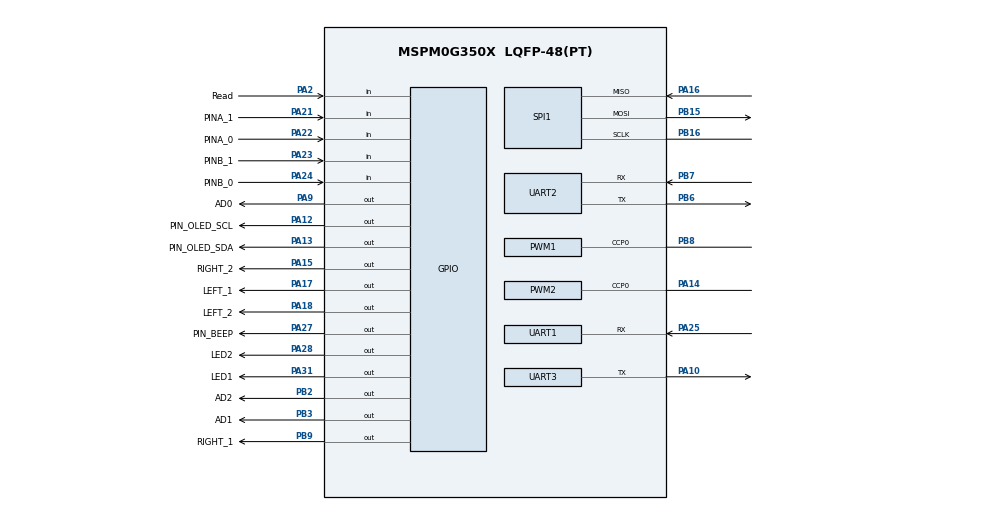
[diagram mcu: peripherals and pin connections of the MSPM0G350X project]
/**
 * @cliArgs --device "MSPM0G350X" --part "Default" --package "LQFP-48(PT)" --product "mspm0_sdk@2.10.00.04"
 * @versions {"tool":"1.26.2+4477"}
 */

/**
 * Import the modules used in this configuration.
 */
const GPIO   = scripting.addModule("/ti/driverlib/GPIO", {}, false);
const GPIO1  = GPIO.addInstance();
const GPIO2  = GPIO.addInstance();
const GPIO3  = GPIO.addInstance();
const GPIO4  = GPIO.addInstance();
const GPIO5  = GPIO.addInstance();
const GPIO6  = GPIO.addInstance();
const GPIO7  = GPIO.addInstance();
const PWM    = scripting.addModule("/ti/driverlib/PWM", {}, false);
const PWM1   = PWM.addInstance();
const PWM2   = PWM.addInstance();
const SPI    = scripting.addModule("/ti/driverlib/SPI", {}, false);
const SPI1   = SPI.addInstance();
const SYSCTL = scripting.addModule("/ti/driverlib/SYSCTL");
const TIMER  = scripting.addModule("/ti/driverlib/TIMER", {}, false);
const TIMER1 = TIMER.addInstance();
const UART   = scripting.addModule("/ti/driverlib/UART", {}, false);
const UART1  = UART.addInstance();
const UART2  = UART.addInstance();
const UART3  = UART.addInstance();

/**
 * Write custom configuration values to the imported modules.
 */
const divider7       = system.clockTree["PLL_PDIV"];
divider7.divideValue = 2;

const divider9       = system.clockTree["UDIV"];
divider9.divideValue = 2;

const multiplier2         = system.clockTree["PLL_QDIV"];
multiplier2.multiplyValue = 5;

const mux8       = system.clockTree["HSCLKMUX"];
mux8.inputSelect = "HSCLKMUX_SYSPLL2X";

GPIO1.$name                         = "GPIO_OLED";
GPIO1.associatedPins.create(2);
GPIO1.associatedPins[0].$name       = "PIN_OLED_SDA";
GPIO1.associatedPins[0].pin.$assign = "PA13";
GPIO1.associatedPins[1].$name       = "PIN_OLED_SCL";
GPIO1.associatedPins[1].pin.$assign = "PA12";

const Board = scripting.addModule("/ti/driverlib/Board", {}, false);

GPIO2.$name                         = "GPIO_MOTOR";
GPIO2.associatedPins.create(4);
GPIO2.associatedPins[0].$name       = "LEFT_1";
GPIO2.associatedPins[0].pin.$assign = "PA17";
GPIO2.associatedPins[1].$name       = "LEFT_2";
GPIO2.associatedPins[1].pin.$assign = "PA18";
GPIO2.associatedPins[2].$name       = "RIGHT_1";
GPIO2.associatedPins[2].pin.$assign = "PB9";
GPIO2.associatedPins[3].$name       = "RIGHT_2";
GPIO2.associatedPins[3].pin.$assign = "PA15";

GPIO3.$name                              = "GPIO_Grayscale";
GPIO3.associatedPins.create(4);
GPIO3.associatedPins[0].direction        = "INPUT";
GPIO3.associatedPins[0].ioStructure      = "SD";
GPIO3.associatedPins[0].$name            = "Read";
GPIO3.associatedPins[0].internalResistor = "PULL_DOWN";
GPIO3.associatedPins[0].pin.$assign      = "PA2";
GPIO3.associatedPins[1].$name            = "AD0";
GPIO3.associatedPins[1].pin.$assign      = "PA9";
GPIO3.associatedPins[2].$name            = "AD1";
GPIO3.associatedPins[2].pin.$assign      = "PB3";
GPIO3.associatedPins[3].$name            = "AD2";
GPIO3.associatedPins[3].pin.$assign      = "PB2";

GPIO4.$name                         = "GPIO_BEEP";
GPIO4.associatedPins[0].$name       = "PIN_BEEP";
GPIO4.associatedPins[0].pin.$assign = "PA27";

GPIO5.$name                          = "GPIO_LED";
GPIO5.associatedPins.create(2);
GPIO5.associatedPins[0].$name        = "LED1";
GPIO5.associatedPins[0].initialValue = "SET";
GPIO5.associatedPins[0].pin.$assign  = "PA31";
GPIO5.associatedPins[1].$name        = "LED2";
GPIO5.associatedPins[1].initialValue = "SET";
GPIO5.associatedPins[1].pin.$assign  = "PA28";

GPIO6.$name                               = "GPIO_EncoderA";
GPIO6.associatedPins.create(2);
GPIO6.associatedPins[0].direction         = "INPUT";
GPIO6.associatedPins[0].interruptEn       = true;
GPIO6.associatedPins[0].interruptPriority = "1";
GPIO6.associatedPins[0].polarity          = "RISE";
GPIO6.associatedPins[0].$name             = "PINA_0";
GPIO6.associatedPins[0].pin.$assign       = "PA22";
GPIO6.associatedPins[1].direction         = "INPUT";
GPIO6.associatedPins[1].interruptEn       = true;
GPIO6.associatedPins[1].interruptPriority = "1";
GPIO6.associatedPins[1].polarity          = "RISE";
GPIO6.associatedPins[1].$name             = "PINA_1";
GPIO6.associatedPins[1].pin.$assign       = "PA21";

GPIO7.$name                               = "GPIO_EncoderB";
GPIO7.associatedPins.create(2);
GPIO7.associatedPins[0].$name             = "PINB_0";
GPIO7.associatedPins[0].direction         = "INPUT";
GPIO7.associatedPins[0].interruptEn       = true;
GPIO7.associatedPins[0].polarity          = "RISE";
GPIO7.associatedPins[0].interruptPriority = "1";
GPIO7.associatedPins[0].pin.$assign       = "PA24";
GPIO7.associatedPins[1].$name             = "PINB_1";
GPIO7.associatedPins[1].direction         = "INPUT";
GPIO7.associatedPins[1].interruptEn       = true;
GPIO7.associatedPins[1].polarity          = "RISE";
GPIO7.associatedPins[1].interruptPriority = "1";
GPIO7.associatedPins[1].pin.$assign       = "PA23";

PWM1.$name                              = "PWM_L";
PWM1.timerStartTimer                    = true;
PWM1.clockDivider                       = 4;
PWM1.timerCount                         = 100;
PWM1.pwmMode                            = "EDGE_ALIGN_UP";
PWM1.clockPrescale                      = 10;
PWM1.ccIndex                            = [0];
PWM1.PWM_CHANNEL_0.$name                = "ti_driverlib_pwm_PWMTimerCC0";
PWM1.ccp0PinConfig.$name                = "ti_driverlib_gpio_GPIOPinGeneric0";
PWM1.ccp0PinConfig.direction            = scripting.forceWrite("OUTPUT");
PWM1.ccp0PinConfig.hideOutputInversion  = scripting.forceWrite(false);
PWM1.ccp0PinConfig.onlyInternalResistor = scripting.forceWrite(false);
PWM1.ccp0PinConfig.passedPeripheralType = scripting.forceWrite("Digital");
PWM1.peripheral.$assign                 = "TIMA0";
PWM1.peripheral.ccp0Pin.$assign         = "PB8";

PWM2.timerStartTimer                    = true;
PWM2.clockDivider                       = 4;
PWM2.pwmMode                            = "EDGE_ALIGN_UP";
PWM2.$name                              = "PWM_R";
PWM2.ccIndex                            = [0];
PWM2.PWM_CHANNEL_0.$name                = "ti_driverlib_pwm_PWMTimerCC3";
PWM2.ccp0PinConfig.direction            = scripting.forceWrite("OUTPUT");
PWM2.ccp0PinConfig.hideOutputInversion  = scripting.forceWrite(false);
PWM2.ccp0PinConfig.onlyInternalResistor = scripting.forceWrite(false);
PWM2.ccp0PinConfig.passedPeripheralType = scripting.forceWrite("Digital");
PWM2.ccp0PinConfig.$name                = "ti_driverlib_gpio_GPIOPinGeneric5";
PWM2.peripheral.ccp0Pin.$assign         = "PA14";

SPI1.$name                      = "SPI_0";
SPI1.peripheral.$assign         = "SPI1";
SPI1.peripheral.sclkPin.$assign = "PB16";
SPI1.peripheral.mosiPin.$assign = "PB15";
SPI1.peripheral.misoPin.$assign = "PA16";
SPI1.sclkPinConfig.$name        = "ti_driverlib_gpio_GPIOPinGeneric9";
SPI1.mosiPinConfig.$name        = "ti_driverlib_gpio_GPIOPinGeneric10";
SPI1.misoPinConfig.$name        = "ti_driverlib_gpio_GPIOPinGeneric11";
SPI1.cs0PinConfig.$name         = "ti_driverlib_gpio_GPIOPinGeneric12";

SYSCTL.forceDefaultClkConfig = true;
SYSCTL.clockTreeEn           = true;

TIMER1.timerClkPrescale   = 256;
TIMER1.timerPeriod        = "50 ms";
TIMER1.interrupts         = ["ZERO"];
TIMER1.$name              = "TIMER_Encoder_Read";
TIMER1.peripheral.$assign = "TIMG6";

UART1.$name                            = "UART_WIT";
UART1.targetBaudRate                   = 115200;
UART1.direction                        = "RX";
UART1.enableFIFO                       = true;
UART1.rxTimeoutValue                   = 1;
UART1.enabledInterrupts                = ["RX_TIMEOUT_ERROR"];
UART1.enabledDMARXTriggers             = "DL_UART_DMA_INTERRUPT_RX";
UART1.rxPinConfig.hideOutputInversion  = scripting.forceWrite(false);
UART1.rxPinConfig.onlyInternalResistor = scripting.forceWrite(false);
UART1.rxPinConfig.passedPeripheralType = scripting.forceWrite("Digital");
UART1.rxPinConfig.$name                = "ti_driverlib_gpio_GPIOPinGeneric1";
UART1.peripheral.$assign               = "UART3";
UART1.peripheral.rxPin.$assign         = "PA25";
UART1.DMA_CHANNEL_RX.$name             = "DMA_WIT";
UART1.DMA_CHANNEL_RX.addressMode       = "f2b";
UART1.DMA_CHANNEL_RX.srcLength         = "BYTE";
UART1.DMA_CHANNEL_RX.dstLength         = "BYTE";

UART2.$name                            = "UART_VISION";
UART2.peripheral.rxPin.$assign         = "PB7";
UART2.peripheral.txPin.$assign         = "PB6";
UART2.txPinConfig.direction            = scripting.forceWrite("OUTPUT");
UART2.txPinConfig.hideOutputInversion  = scripting.forceWrite(false);
UART2.txPinConfig.onlyInternalResistor = scripting.forceWrite(false);
UART2.txPinConfig.passedPeripheralType = scripting.forceWrite("Digital");
UART2.txPinConfig.$name                = "ti_driverlib_gpio_GPIOPinGeneric2";
UART2.rxPinConfig.hideOutputInversion  = scripting.forceWrite(false);
UART2.rxPinConfig.onlyInternalResistor = scripting.forceWrite(false);
UART2.rxPinConfig.passedPeripheralType = scripting.forceWrite("Digital");
UART2.rxPinConfig.$name                = "ti_driverlib_gpio_GPIOPinGeneric3";

UART3.$name                            = "UART_BLUETEETH";
UART3.uartClkSrc                       = "LFCLK";
UART3.enableFIFO                       = true;
UART3.rxFifoThreshold                  = "DL_UART_RX_FIFO_LEVEL_ONE_ENTRY";
UART3.enableDMARX                      = false;
UART3.enableDMATX                      = false;
UART3.direction                        = "TX";
UART3.ovsRate                          = "3";
UART3.txPinConfig.direction            = scripting.forceWrite("OUTPUT");
UART3.txPinConfig.hideOutputInversion  = scripting.forceWrite(false);
UART3.txPinConfig.onlyInternalResistor = scripting.forceWrite(false);
UART3.txPinConfig.passedPeripheralType = scripting.forceWrite("Digital");
UART3.txPinConfig.$name                = "ti_driverlib_gpio_GPIOPinGeneric4";
UART3.peripheral.$assign               = "UART0";
UART3.peripheral.txPin.$assign         = "PA10";

const ProjectConfig              = scripting.addModule("/ti/project_config/ProjectConfig", {}, false);
ProjectConfig.migrationCondition = true;

/**
 * Pinmux solution for unlocked pins/peripherals. This ensures that minor changes to the automatic solver in a future
 * version of the tool will not impact the pinmux you originally saw.  These lines can be completely deleted in order to
 * re-solve from scratch.
 */
Board.peripheral.$suggestSolution                = "DEBUGSS";
Board.peripheral.swclkPin.$suggestSolution       = "PA20";
Board.peripheral.swdioPin.$suggestSolution       = "PA19";
PWM2.peripheral.$suggestSolution                 = "TIMG12";
SPI1.peripheral.cs0Pin.$suggestSolution          = "PA26";
UART1.DMA_CHANNEL_RX.peripheral.$suggestSolution = "DMA_CH0";
UART2.peripheral.$suggestSolution                = "UART1";
